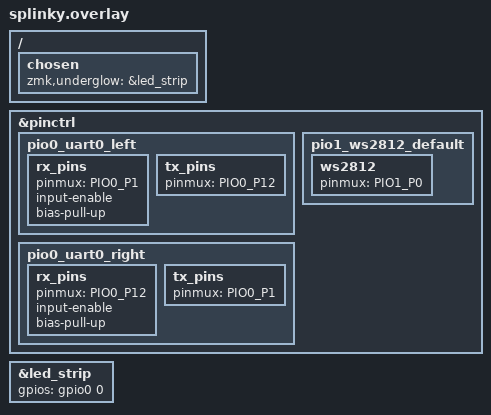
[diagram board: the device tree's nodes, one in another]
&pinctrl {
    pio0_uart0_left: pio0_uart0_left {
        rx_pins {
            pinmux = <PIO0_P1>;
            input-enable;
            bias-pull-up;
        };
        tx_pins {
            pinmux = <PIO0_P12>;
        };
    };
    pio0_uart0_right: pio0_uart0_right {
        rx_pins {
            pinmux = <PIO0_P12>;
            input-enable;
            bias-pull-up;
        };
        tx_pins {
            pinmux = <PIO0_P1>;
        };
    };

    /* WS2812 LED strip on GP0 for splinky */
    pio1_ws2812_default: pio1_ws2812_default {
        ws2812 {
            pinmux = <PIO1_P0>;
        };
    };
};

&led_strip {
    gpios = <&gpio0 0 GPIO_ACTIVE_HIGH>;
};

/ {
    chosen {
        zmk,underglow = &led_strip;
    };
};
